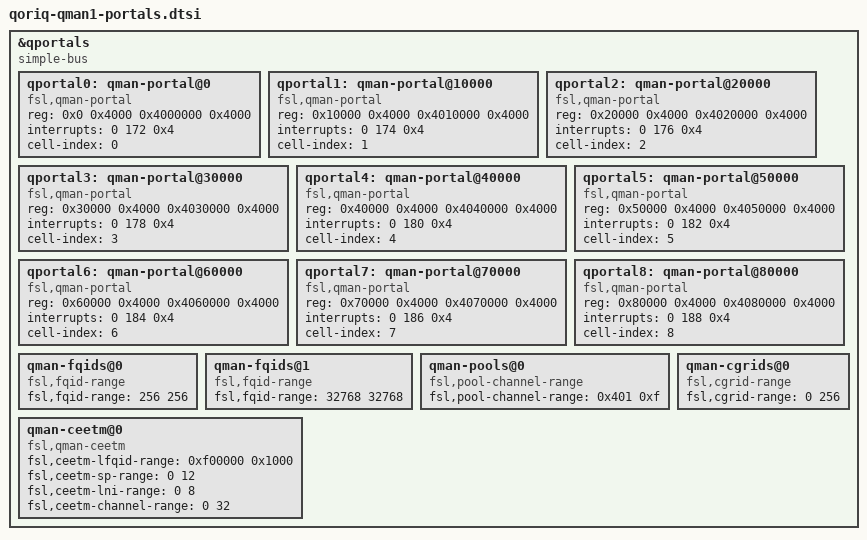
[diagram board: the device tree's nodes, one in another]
/*
 * QorIQ QMan Portals device tree
 *
 * Copyright 2011-2016 Freescale Semiconductor Inc.
 *
 * SPDX-License-Identifier: (GPL-2.0+ OR BSD-3-Clause)
 */

&qportals {
	#address-cells = <1>;
	#size-cells = <1>;
	compatible = "simple-bus";

	qportal0: qman-portal@0 {
		compatible = "fsl,qman-portal";
		reg = <0x0 0x4000 0x4000000 0x4000>;
		interrupts = <0 172 0x4>;
		cell-index = <0>;
	};

	qportal1: qman-portal@10000 {
		compatible = "fsl,qman-portal";
		reg = <0x10000 0x4000 0x4010000 0x4000>;
		interrupts = <0 174 0x4>;
		cell-index = <1>;
	};

	qportal2: qman-portal@20000 {
		compatible = "fsl,qman-portal";
		reg = <0x20000 0x4000 0x4020000 0x4000>;
		interrupts = <0 176 0x4>;
		cell-index = <2>;
	};

	qportal3: qman-portal@30000 {
		compatible = "fsl,qman-portal";
		reg = <0x30000 0x4000 0x4030000 0x4000>;
		interrupts = <0 178 0x4>;
		cell-index = <3>;
	};

	qportal4: qman-portal@40000 {
		compatible = "fsl,qman-portal";
		reg = <0x40000 0x4000 0x4040000 0x4000>;
		interrupts = <0 180 0x4>;
		cell-index = <4>;
	};

	qportal5: qman-portal@50000 {
		compatible = "fsl,qman-portal";
		reg = <0x50000 0x4000 0x4050000 0x4000>;
		interrupts = <0 182 0x4>;
		cell-index = <5>;
	};

	qportal6: qman-portal@60000 {
		compatible = "fsl,qman-portal";
		reg = <0x60000 0x4000 0x4060000 0x4000>;
		interrupts = <0 184 0x4>;
		cell-index = <6>;
	};

	qportal7: qman-portal@70000 {
		compatible = "fsl,qman-portal";
		reg = <0x70000 0x4000 0x4070000 0x4000>;
		interrupts = <0 186 0x4>;
		cell-index = <7>;
	};

	qportal8: qman-portal@80000 {
		compatible = "fsl,qman-portal";
		reg = <0x80000 0x4000 0x4080000 0x4000>;
		interrupts = <0 188 0x4>;
		cell-index = <8>;
	};

	qman-fqids@0 {
		compatible = "fsl,fqid-range";
		fsl,fqid-range = <256 256>;
	};

	qman-fqids@1 {
		compatible = "fsl,fqid-range";
		fsl,fqid-range = <32768 32768>;
	};

	qman-pools@0 {
		compatible = "fsl,pool-channel-range";
		fsl,pool-channel-range = <0x401 0xf>;
	};

	qman-cgrids@0 {
		compatible = "fsl,cgrid-range";
		fsl,cgrid-range = <0 256>;
	};

	qman-ceetm@0 {
		compatible = "fsl,qman-ceetm";
		fsl,ceetm-lfqid-range = <0xf00000 0x1000>;
		fsl,ceetm-sp-range = <0 12>;
		fsl,ceetm-lni-range = <0 8>;
		fsl,ceetm-channel-range = <0 32>;
	};
};
